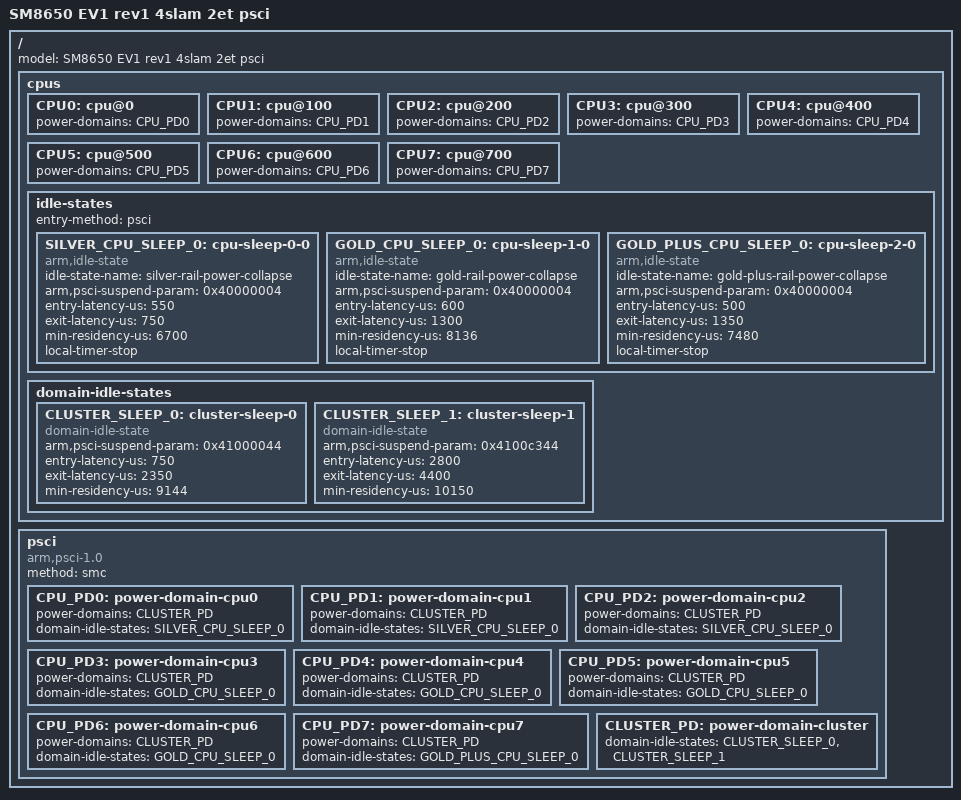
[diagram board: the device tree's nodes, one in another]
/dts-v1/;

#include "sm8650-ev1.dts"

/ {
    model = "SM8650 EV1 rev1 4slam 2et psci";

	cpus {

		CPU0: cpu@0 {
			power-domains = <&CPU_PD0>;
			power-domain-names = "psci";
		};

		CPU1: cpu@100 {
			power-domains = <&CPU_PD1>;
			power-domain-names = "psci";
		};

		CPU2: cpu@200 {
			power-domains = <&CPU_PD2>;
			power-domain-names = "psci";
		};

		CPU3: cpu@300 {
			power-domains = <&CPU_PD3>;
			power-domain-names = "psci";
		};

		CPU4: cpu@400 {
			power-domains = <&CPU_PD4>;
			power-domain-names = "psci";
		};

		CPU5: cpu@500 {
			power-domains = <&CPU_PD5>;
			power-domain-names = "psci";
		};

		CPU6: cpu@600 {
			power-domains = <&CPU_PD6>;
			power-domain-names = "psci";
		};

		CPU7: cpu@700 {
			power-domains = <&CPU_PD7>;
			power-domain-names = "psci";
		};

		idle-states {
			entry-method = "psci";

			SILVER_CPU_SLEEP_0: cpu-sleep-0-0 {
				compatible = "arm,idle-state";
				idle-state-name = "silver-rail-power-collapse";
				arm,psci-suspend-param = <0x40000004>;
				entry-latency-us = <550>;
				exit-latency-us = <750>;
				min-residency-us = <6700>;
				local-timer-stop;
			};

			GOLD_CPU_SLEEP_0: cpu-sleep-1-0 {
				compatible = "arm,idle-state";
				idle-state-name = "gold-rail-power-collapse";
				arm,psci-suspend-param = <0x40000004>;
				entry-latency-us = <600>;
				exit-latency-us = <1300>;
				min-residency-us = <8136>;
				local-timer-stop;
			};

			GOLD_PLUS_CPU_SLEEP_0: cpu-sleep-2-0 {
				compatible = "arm,idle-state";
				idle-state-name = "gold-plus-rail-power-collapse";
				arm,psci-suspend-param = <0x40000004>;
				entry-latency-us = <500>;
				exit-latency-us = <1350>;
				min-residency-us = <7480>;
				local-timer-stop;
			};
		};

		domain-idle-states {
			CLUSTER_SLEEP_0: cluster-sleep-0 {
				compatible = "domain-idle-state";
				arm,psci-suspend-param = <0x41000044>;
				entry-latency-us = <750>;
				exit-latency-us = <2350>;
				min-residency-us = <9144>;
			};

			CLUSTER_SLEEP_1: cluster-sleep-1 {
				compatible = "domain-idle-state";
				arm,psci-suspend-param = <0x4100c344>;
				entry-latency-us = <2800>;
				exit-latency-us = <4400>;
				min-residency-us = <10150>;
			};
		};
	};



	psci {
		compatible = "arm,psci-1.0";
		method = "smc";

		CPU_PD0: power-domain-cpu0 {
			#power-domain-cells = <0>;
			power-domains = <&CLUSTER_PD>;
			domain-idle-states = <&SILVER_CPU_SLEEP_0>;
		};

		CPU_PD1: power-domain-cpu1 {
			#power-domain-cells = <0>;
			power-domains = <&CLUSTER_PD>;
			domain-idle-states = <&SILVER_CPU_SLEEP_0>;
		};

		CPU_PD2: power-domain-cpu2 {
			#power-domain-cells = <0>;
			power-domains = <&CLUSTER_PD>;
			domain-idle-states = <&SILVER_CPU_SLEEP_0>;
		};

		CPU_PD3: power-domain-cpu3 {
			#power-domain-cells = <0>;
			power-domains = <&CLUSTER_PD>;
			domain-idle-states = <&GOLD_CPU_SLEEP_0>;
		};

		CPU_PD4: power-domain-cpu4 {
			#power-domain-cells = <0>;
			power-domains = <&CLUSTER_PD>;
			domain-idle-states = <&GOLD_CPU_SLEEP_0>;
		};

		CPU_PD5: power-domain-cpu5 {
			#power-domain-cells = <0>;
			power-domains = <&CLUSTER_PD>;
			domain-idle-states = <&GOLD_CPU_SLEEP_0>;
		};

		CPU_PD6: power-domain-cpu6 {
			#power-domain-cells = <0>;
			power-domains = <&CLUSTER_PD>;
			domain-idle-states = <&GOLD_CPU_SLEEP_0>;
		};

		CPU_PD7: power-domain-cpu7 {
			#power-domain-cells = <0>;
			power-domains = <&CLUSTER_PD>;
			domain-idle-states = <&GOLD_PLUS_CPU_SLEEP_0>;
		};

		CLUSTER_PD: power-domain-cluster {
			#power-domain-cells = <0>;
			domain-idle-states = <&CLUSTER_SLEEP_0>,
					     <&CLUSTER_SLEEP_1>;
		};
	};

};
